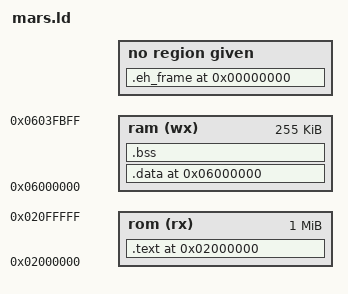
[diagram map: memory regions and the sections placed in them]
OUTPUT_ARCH(sh)
SEARCH_DIR(.)

/* The memory map look like this:
 * +--------------------+ <- 0x02000000
 * | .text              |
 * |        _etext      |
 * |        ctor list   | the ctor and dtor lists are for
 * |        dtor list   | C++ support
 * +--------------------+
 * .                    .
 * .                    .
 * .                    .
 * +--------------------+ <- 0x06000000
 * | .data              | initialized data goes here
 * |        _edata      |
 * +--------------------+
 * | .bss               |
 * |        __bss_start | start of bss, cleared by crt0
 * |        _end        | start of heap, used by sbrk()
 * +--------------------+
 * .                    .
 * .                    .
 * .                    .
 * |        __stack     | top of stack (for Master SH2)
 * +--------------------+ <- 0x0603FC00
 */

/* rom now covers the whole of cartridge bank 0 (1 MB): every asset that used
 * to carve its own reserved MEMORY region out of this space (sonicrot,
 * objtiles, maphigh, ghztiles -- the old "change one, change all three"
 * hand-synced quartets, one per asset) has moved to cartridge bank 1
 * instead, generated wholesale by tools/gen_assets.py -- see bank1's own
 * comment below. The 68000's stricter limit, its program staying inside the
 * fixed 512 KB cartridge window, is enforced separately by the
 * M68K_CODE_END ASSERT at the bottom of this script; today's 68000 program
 * is CODE ONLY (every asset it used to .incbin now lives in bank1 instead),
 * so it uses a small fraction of that window, and rom's own much larger
 * LENGTH here is headroom for the SH2 program's OWN code to grow into, not
 * a hazard the way it briefly was when this region had to leave room for
 * sonicrot/objtiles/maphigh right after it. */
MEMORY {
	rom (rx) : ORIGIN = 0x02000000, LENGTH = 0x00100000
	ram (wx) : ORIGIN = 0x06000000, LENGTH = 0x0003FC00

	/* Cartridge bank 1 (0x100000-0x1FFFFF): every converted asset in the
	 * game, for both CPUs, generated by tools/gen_assets.py from that
	 * script's own manifest. INCLUDEd here is just this region's ORIGIN/
	 * LENGTH (sh_src/mars_gen_mem.ld); the matching per-asset SECTIONS
	 * entries are INCLUDEd into the SECTIONS block below
	 * (sh_src/mars_gen_sections.ld), the SH2-side .incbin file is generated
	 * sh_src/assets_gen.s, and the 68000-side fixed-pointer header is
	 * generated md_src/assets_gen.h -- one manifest, these four generated
	 * outputs, nothing hand-synced between them.
	 *
	 * The 68000 reaches this whole region through the banked window
	 * (0x900000-0x9FFFFF, md_src/bank.h) after selecting bank 1 exactly
	 * once, at boot (main.c) -- and never switches away again, since
	 * nothing the 68000 reads through that window lives anywhere else any
	 * more. The SH2s reach it directly at this region's ORIGIN, no bank
	 * switch involved at all (SH2s address the cartridge linearly). */
	INCLUDE sh_src/mars_gen_mem.ld
}

PROVIDE (__stack = 0x0603FC00);

SECTIONS {
	.text 0x02000000 : AT(0x00000000) {
		*(.text .text.*)
		. = ALIGN(0x4);

		__CTOR_LIST__ = .;
		___CTOR_LIST__ = .;
		LONG((__CTOR_END__ - __CTOR_LIST__) / 4 - 2)
		*(.ctors)
		LONG(0)
		__CTOR_END__ = .;
		__DTOR_LIST__ = .;
		___DTOR_LIST__ = .;
		LONG((__DTOR_END__ - __DTOR_LIST__) / 4 - 2)
		*(.dtors)
		LONG(0)
		__DTOR_END__ = .;
		*(.rodata .rodata.*)
		*(.gcc_except_table .gcc_except_table.*)

		. = ALIGN(0x10);
		__INIT_SECTION__ = . ;
		*(.init)
		SHORT (0x000B)	/* rts */
		SHORT (0x0009)	/* nop */

		. = ALIGN(0x10);
		__FINI_SECTION__ = . ;
		*(.fini)
		SHORT (0x000B)	/* rts */
		SHORT (0x0009)	/* nop */

		_etext = .;
		*(.lit)
		. = ALIGN(0x4);
	} > rom
	_stext = SIZEOF (.text);

	/* Every asset's own SECTIONS entry (KEEP, fixed VMA/AT() pair, same
	 * convention .text above uses for the flat .32x image's LMA), generated
	 * from tools/gen_assets.py's manifest -- see MEMORY's bank1 comment
	 * above and sh_src/mars_gen_sections.ld itself. */
	INCLUDE sh_src/mars_gen_sections.ld

	.data 0x06000000 : AT(LOADADDR(.text) + SIZEOF(.text)) {
		*(.got.plt) *(.got)
		*(.shdata)
		*(.data .data.*)
		_edata = .;
		. = ALIGN(0x4);
	} > ram
	_sdata = SIZEOF (.data);

	.bss 0x06000000 + SIZEOF(.data) :
	{
		__bss_start = . ;
		*(.shbss)
		*(.bss .bss.*)
		*(COMMON)
		_end =  ALIGN (0x8);
		__end = _end;
		end = _end;
	} > ram

	.eh_frame 0 (NOLOAD) :
	{
		*(.eh_frame)
	}
}

/* The 68000-visible program (mars_start.s's M68K_CODE incbin) must stay
 * inside the 68000's fixed 512 KB cartridge window; rom's LENGTH does not
 * enforce that on its own since it covers all of bank 0 (1 MB), not just
 * the 68000's fixed window's own 512 KB half of it. */
ASSERT(M68K_CODE_END <= 0x02080000, "68000 program spills past its fixed 512 KB cartridge window")
